VERSION "created by canmatrix"

NS_ :

BS_:

BU_: Host RT SYS MTR HMI Any

BO_ 1 SAFETY_ESTOP: 0 Any

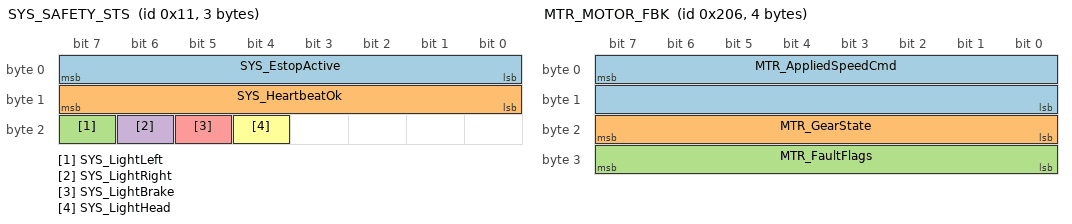
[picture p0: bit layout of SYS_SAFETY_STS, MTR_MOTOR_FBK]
BO_ 17 SYS_SAFETY_STS: 3 SYS
 SG_ SYS_EstopActive : 7|8@0+ (1,0) [0|1] "" Vector__XXX
 SG_ SYS_HeartbeatOk : 15|8@0+ (1,0) [0|1] "" Vector__XXX
 SG_ SYS_LightLeft : 23|1@0+ (1,0) [0|1] "" Vector__XXX
 SG_ SYS_LightRight : 22|1@0+ (1,0) [0|1] "" Vector__XXX
 SG_ SYS_LightBrake : 21|1@0+ (1,0) [0|1] "" Vector__XXX
 SG_ SYS_LightHead : 20|1@0+ (1,0) [0|1] "" Vector__XXX

BO_ 272 SYS_MODE_CMD: 1 SYS
 SG_ SYS_Mode : 7|8@0+ (1,0) [0|2] "" Vector__XXX

BO_ 273 HMI_MODE_REQ: 2 HMI
 SG_ HMI_ReqMode : 7|8@0+ (1,0) [0|1] "" Vector__XXX
 SG_ HMI_ModeAlive : 15|8@0+ (1,0) [0|255] "" Vector__XXX

BO_ 274 HMI_PWR_REQ: 2 HMI
 SG_ HMI_ReqStart : 7|8@0+ (1,0) [0|1] "" Vector__XXX
 SG_ HMI_PwrAlive : 15|8@0+ (1,0) [0|255] "" Vector__XXX

BO_ 288 SYS_THROTTLE_STS: 2 MTR
 SG_ SYS_ThrottleSpeed : 7|16@0- (1,0) [-500|3000] "mm/s" Vector__XXX

BO_ 516 RT_DRIVE_CMD: 5 RT
 SG_ RT_MotorSpeed : 7|32@0- (1,0) [-500|3000] "mm/s" Vector__XXX
 SG_ RT_Gear : 39|8@0+ (1,0) [0|3] "enum" Vector__XXX

BO_ 517 RT_BRAKE_CMD: 4 RT
 SG_ RT_BrakePressure : 7|32@0- (1,0) [0|20000] "kPa" Vector__XXX

BO_ 518 MTR_MOTOR_FBK: 4 MTR
 SG_ MTR_AppliedSpeedCmd : 7|16@0- (1,0) [-500|3000] "mm/s" Vector__XXX
 SG_ MTR_GearState : 23|8@0+ (1,0) [0|3] "" Vector__XXX
 SG_ MTR_FaultFlags : 31|8@0+ (1,0) [0|255] "" Vector__XXX

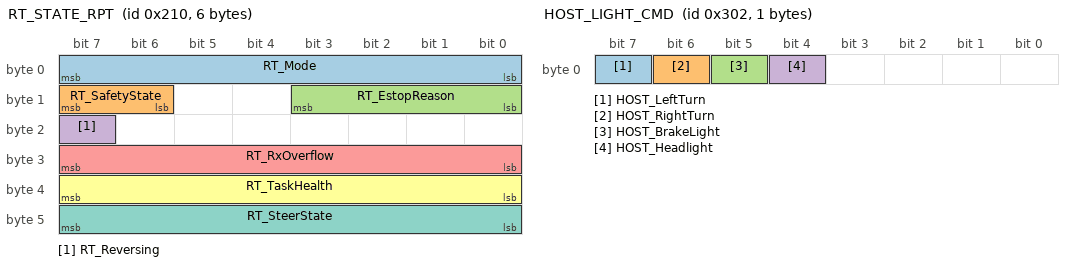
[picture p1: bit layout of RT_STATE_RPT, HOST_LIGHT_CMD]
BO_ 528 RT_STATE_RPT: 6 RT
 SG_ RT_Mode : 7|8@0+ (1,0) [0|2] "" Vector__XXX
 SG_ RT_SafetyState : 15|2@0+ (1,0) [0|2] "" Vector__XXX
 SG_ RT_EstopReason : 11|4@0+ (1,0) [0|7] "" Vector__XXX
 SG_ RT_Reversing : 23|1@0+ (1,0) [0|1] "" Vector__XXX
 SG_ RT_RxOverflow : 31|8@0+ (1,0) [0|255] "" Vector__XXX
 SG_ RT_TaskHealth : 39|8@0+ (1,0) [0|255] "" Vector__XXX
 SG_ RT_SteerState : 47|8@0+ (1,0) [0|5] "" Vector__XXX

BO_ 770 HOST_LIGHT_CMD: 1 Host
 SG_ HOST_LeftTurn : 7|1@0+ (1,0) [0|1] "" Vector__XXX
 SG_ HOST_RightTurn : 6|1@0+ (1,0) [0|1] "" Vector__XXX
 SG_ HOST_BrakeLight : 5|1@0+ (1,0) [0|1] "" Vector__XXX
 SG_ HOST_Headlight : 4|1@0+ (1,0) [0|1] "" Vector__XXX

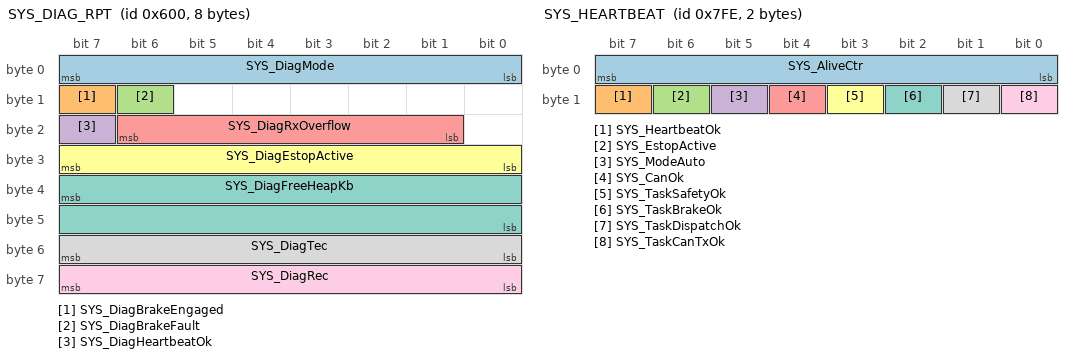
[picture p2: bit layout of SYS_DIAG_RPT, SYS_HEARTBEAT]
BO_ 1536 SYS_DIAG_RPT: 8 SYS
 SG_ SYS_DiagMode : 7|8@0+ (1,0) [0|2] "" Vector__XXX
 SG_ SYS_DiagBrakeEngaged : 15|1@0+ (1,0) [0|1] "" Vector__XXX
 SG_ SYS_DiagBrakeFault : 14|1@0+ (1,0) [0|1] "" Vector__XXX
 SG_ SYS_DiagHeartbeatOk : 23|1@0+ (1,0) [0|1] "" Vector__XXX
 SG_ SYS_DiagRxOverflow : 22|6@0+ (1,0) [0|63] "" Vector__XXX
 SG_ SYS_DiagEstopActive : 31|8@0+ (1,0) [0|1] "" Vector__XXX
 SG_ SYS_DiagFreeHeapKb : 39|16@0+ (1,0) [0|65535] "KB" Vector__XXX
 SG_ SYS_DiagTec : 55|8@0+ (1,0) [0|255] "" Vector__XXX
 SG_ SYS_DiagRec : 63|8@0+ (1,0) [0|255] "" Vector__XXX

BO_ 2045 RT_HEARTBEAT: 2 RT
 SG_ RT_AliveCtr : 7|8@0+ (1,0) [0|255] "" Vector__XXX
 SG_ RT_HealthFlags : 15|8@0+ (1,0) [0|255] "" Vector__XXX

BO_ 2046 SYS_HEARTBEAT: 2 SYS
 SG_ SYS_AliveCtr : 7|8@0+ (1,0) [0|255] "" Vector__XXX
 SG_ SYS_HeartbeatOk : 15|1@0+ (1,0) [0|1] "" Vector__XXX
 SG_ SYS_EstopActive : 14|1@0+ (1,0) [0|1] "" Vector__XXX
 SG_ SYS_ModeAuto : 13|1@0+ (1,0) [0|1] "" Vector__XXX
 SG_ SYS_CanOk : 12|1@0+ (1,0) [0|1] "" Vector__XXX
 SG_ SYS_TaskSafetyOk : 11|1@0+ (1,0) [0|1] "" Vector__XXX
 SG_ SYS_TaskBrakeOk : 10|1@0+ (1,0) [0|1] "" Vector__XXX
 SG_ SYS_TaskDispatchOk : 9|1@0+ (1,0) [0|1] "" Vector__XXX
 SG_ SYS_TaskCanTxOk : 8|1@0+ (1,0) [0|1] "" Vector__XXX

CM_ BO_ 1  "DLC=0  the frame ID itself is the ESTOP signal. Any node can send (RT is nominal). Bridged bidirectionally. Highest priority CAN frame.";
CM_ BO_ 17  "Forwarded lowhigh by RT. Same payload on both buses. DLC=3 adds light state (v0.0.5).";
CM_ BO_ 272  "0=Manual, 1=Auto, 2=ESTOP. Low bus only. MTR needs mode for pass-through vs CAN control.";
CM_ BO_ 273  "HMI mode request. 1Hz periodic heartbeat. Forwarded highlow by RT.";
CM_ BO_ 274  "HMI power request. 1Hz periodic heartbeat. Forwarded highlow by RT.";
CM_ BO_ 288  "Current vehicle speed from MTR STM32. Forwarded lowhigh by RT. SYS_ prefix is historical.";
CM_ BO_ 516  "MTR receives for motor actuation. SYS receives for EGAS L2 monitoring. ID 0x204 avoids collision with EPS-C 0x202.";
CM_ BO_ 517  "RT max-select: max(rt_obstacle, host_0x301) -> SYS SEB cmd.";
CM_ BO_ 518  "Motor feedback from STM32. Forwarded lowhigh by RT per gateway rules.";
CM_ BO_ 528  "RT state report to Host (high bus) and SYS (low bus). SYS monitors safety_state for takeover detection and RT health.";
CM_ BO_ 770  "Forwarded transparently highlow by RT.";
CM_ BO_ 1536  "SYS diagnostics report. Forwarded lowhigh by RT.";
CM_ BO_ 2045  "RT sends independently on both buses (per-bus, NOT bridged). Separate counters. This is the low-bus instance.";
CM_ BO_ 2046  "Low bus only, never leaves low bus.";

CM_ SG_ 17 SYS_HeartbeatOk "0=RT alive counter frozen >1000ms, 1=incrementing";
CM_ SG_ 273 HMI_ModeAlive "Rolling counter for UI health";
CM_ SG_ 274 HMI_PwrAlive "Rolling counter for UI health";
CM_ SG_ 518 MTR_FaultFlags "bit0=ESTOP, bit1=CMD timeout, bit2=ADC fault, bit3=gear conflict, bit4=MTR startup ready";
CM_ SG_ 528 RT_SafetyState "RT internal state: 0=Normal, 1=Internal ESTOP (steer ramp/hold), 2=Fault";
CM_ SG_ 528 RT_EstopReason "Reason for ESTOP state, packed in byte 1 bits 4-7";
CM_ SG_ 528 RT_RxOverflow "MCP2515 RX overflow counter  telemetry for CAN bus health monitoring";
CM_ SG_ 528 RT_TaskHealth "Bitmask of alive tasks (bits 0-3: control/dispatch/tx_low/tx_high)";
CM_ SG_ 528 RT_SteerState "Steering state machine value";
CM_ SG_ 1536 SYS_DiagBrakeFault "SEB L3 fault or brake following-error active";
CM_ SG_ 1536 SYS_DiagRxOverflow "Saturating SYS TWAI RX overflow count";
CM_ SG_ 2045 RT_AliveCtr "Low bus timeout 1000ms->SYS ESTOP";
CM_ SG_ 2045 RT_HealthFlags "bit0=heartbeat_ok, bit1=estop_active, bit2=mode_auto, bit3=can_ok, bits4-7=reserved";
CM_ SG_ 2046 SYS_AliveCtr "10 Hz / 200ms timeout -> RT brake takeover + ESTOP";

CM_ BU_ Host "Orin NX, Linux + ROS 2, perception/planning";
CM_ BU_ RT "ESP32-S3, FreeRTOS, realtime kinematics + CAN gateway";
CM_ BU_ SYS "ESP32-S3, FreeRTOS, safety + motor + body control";
CM_ BU_ MTR "STM32, bare metal, motor DAC + gear relays (EGAS L1)";
CM_ BU_ HMI "CAN Controller UI / Dashboard, mode and power requests";
CM_ BU_ Any "Wildcard  any node may send (e.g., ESTOP frames)";

BA_DEF_ BO_ "GenMsgCycleTime" INT 0 65535;

BA_ "GenMsgCycleTime" BO_ 17 200;
BA_ "GenMsgCycleTime" BO_ 273 1000;
BA_ "GenMsgCycleTime" BO_ 274 1000;
BA_ "GenMsgCycleTime" BO_ 288 10;
BA_ "GenMsgCycleTime" BO_ 516 10;
BA_ "GenMsgCycleTime" BO_ 517 20;
BA_ "GenMsgCycleTime" BO_ 518 20;
BA_ "GenMsgCycleTime" BO_ 528 100;
BA_ "GenMsgCycleTime" BO_ 1536 1000;
BA_ "GenMsgCycleTime" BO_ 2045 500;
BA_ "GenMsgCycleTime" BO_ 2046 100;

VAL_ 273 HMI_ReqMode 0 "MANUAL" 1 "AUTO";
VAL_ 274 HMI_ReqStart 0 "False" 1 "True";
VAL_ 516 RT_Gear 0 "N" 1 "D" 2 "S" 3 "R";
VAL_ 528 RT_Mode 0 "MANUAL" 1 "AUTO" 2 "ESTOP";
VAL_ 528 RT_SafetyState 0 "Normal" 1 "Warning" 2 "Fault";
